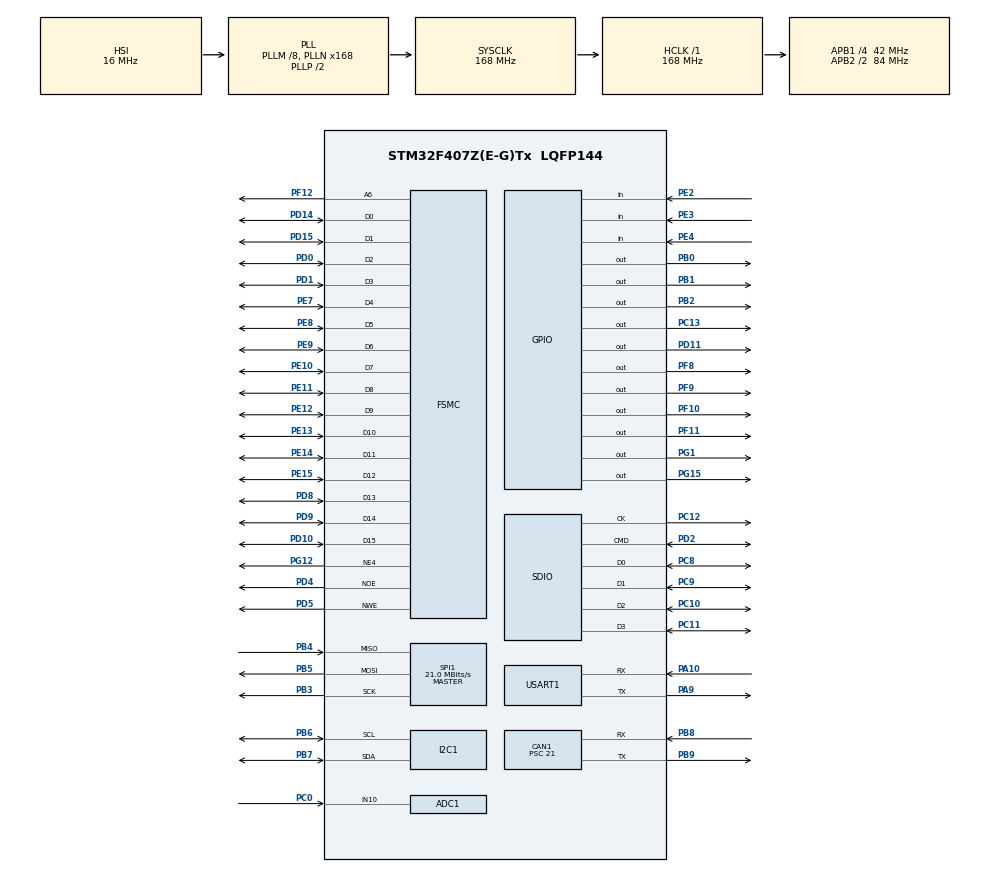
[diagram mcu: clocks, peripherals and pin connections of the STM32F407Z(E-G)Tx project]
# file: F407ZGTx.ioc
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ADC1.Channel-0\#ChannelRegularConversion=ADC_CHANNEL_10
ADC1.ClockPrescaler=ADC_CLOCK_SYNC_PCLK_DIV6
ADC1.ExternalTrigConv=ADC_EXTERNALTRIGCONV_T2_TRGO
ADC1.NbrOfConversion=1
ADC1.NbrOfConversionFlag=1
ADC1.Rank-0\#ChannelRegularConversion=1
ADC1.SamplingTime-0\#ChannelRegularConversion=ADC_SAMPLETIME_480CYCLES
ADC1.master=1
CAN1.ABOM=ENABLE
CAN1.BS1=CAN_BS1_13TQ
CAN1.BS2=CAN_BS2_2TQ
CAN1.CalculateBaudRate=125000
CAN1.CalculateTimeBit=8000
CAN1.CalculateTimeQuantum=500.0
CAN1.Mode=CAN_MODE_LOOPBACK
CAN1.NART=ENABLE
CAN1.Prescaler=21
Dma.ADC1.1.Direction=DMA_PERIPH_TO_MEMORY
Dma.ADC1.1.FIFOMode=DMA_FIFOMODE_DISABLE
Dma.ADC1.1.Instance=DMA2_Stream0
Dma.ADC1.1.MemDataAlignment=DMA_MDATAALIGN_HALFWORD
Dma.ADC1.1.MemInc=DMA_MINC_ENABLE
Dma.ADC1.1.Mode=DMA_CIRCULAR
Dma.ADC1.1.PeriphDataAlignment=DMA_PDATAALIGN_HALFWORD
Dma.ADC1.1.PeriphInc=DMA_PINC_DISABLE
Dma.ADC1.1.Priority=DMA_PRIORITY_LOW
Dma.Request0=USART1_RX
Dma.Request1=ADC1
Dma.USART1_RX.0.Direction=DMA_PERIPH_TO_MEMORY
Dma.USART1_RX.0.FIFOMode=DMA_FIFOMODE_DISABLE
Dma.USART1_RX.0.Instance=DMA2_Stream2
Dma.USART1_RX.0.MemDataAlignment=DMA_MDATAALIGN_BYTE
Dma.USART1_RX.0.MemInc=DMA_MINC_ENABLE
Dma.USART1_RX.0.Mode=DMA_NORMAL
Dma.USART1_RX.0.PeriphDataAlignment=DMA_PDATAALIGN_BYTE
Dma.USART1_RX.0.PeriphInc=DMA_PINC_DISABLE
Dma.USART1_RX.0.Priority=DMA_PRIORITY_LOW
FREERTOS.Queues01=q_LedReq,4,LedReq_t,0,Dynamic,NULL,NULL;q_KeyMsg,16,KeyMsg_t,0,Dynamic,NULL,NULL;q_TouchMsg,16,TouchMsg_t,0,Dynamic,NULL,NULL;q_UiMsg,8,UiMsg_t,0,Dynamic,NULL,NULL;q_Usart1RxMsg,8,UartMsg_t,0,Dynamic,NULL,NULL;q_Usart1TxMsg,8,UartMsg_t,0,Dynamic,NULL,NULL
FREERTOS.Tasks01=defaultTask,8,128,StartDefaultTask,Default,NULL,Dynamic,NULL,NULL;t_Lcd_Disp,16,1536,Lcd_Disp,As weak,NULL,Dynamic,NULL,NULL;t_Led_Disp,16,128,Led_Disp,As weak,NULL,Dynamic,NULL,NULL;t_Key_Proc,32,256,Key_Proc,As weak,NULL,Dynamic,NULL,NULL;t_Touch_Proc,32,256,Touch_Proc,As weak,NULL,Dynamic,NULL,NULL;t_Uart_Send,16,256,Uart_Send,As weak,NULL,Dynamic,NULL,NULL;t_Uart_Recv,16,256,Uart_Recv,As weak,NULL,Dynamic,NULL,NULL
FREERTOS.configTOTAL_HEAP_SIZE=32768
FSMC.AddressSetupTime4=3
FSMC.BusTurnAroundDuration4=0
FSMC.DataSetupTime4=20
FSMC.ExtendedAddressSetupTime4=9
FSMC.ExtendedBusTurnAroundDuration4=0
FSMC.ExtendedDataSetupTime4=8
FSMC.ExtendedMode4=FSMC_EXTENDED_MODE_ENABLE
Mcu.Family=STM32F4
Mcu.Name=STM32F407Z(E-G)Tx
Mcu.Package=LQFP144
NVIC.CAN1_RX0_IRQn=true\:5\:0\:false\:false\:true\:true\:true\:true\:true
NVIC.CAN1_SCE_IRQn=true\:5\:0\:false\:false\:true\:true\:true\:true\:true
NVIC.DMA2_Stream0_IRQn=true\:5\:0\:false\:false\:true\:true\:false\:true\:true
NVIC.DMA2_Stream2_IRQn=true\:5\:0\:false\:false\:true\:true\:false\:true\:true
NVIC.PriorityGroup=NVIC_PRIORITYGROUP_4
NVIC.TIM6_DAC_IRQn=true\:15\:0\:false\:false\:true\:false\:false\:true\:true
NVIC.TimeBase=TIM6_DAC_IRQn
NVIC.TimeBaseIP=TIM6
NVIC.USART1_IRQn=true\:5\:0\:false\:false\:true\:true\:true\:true\:true
PA10.Mode=Asynchronous
PA10.Signal=USART1_RX
PA13.Mode=Serial_Wire
PA13.Signal=SYS_JTMS-SWDIO
PA14.Mode=Serial_Wire
PA14.Signal=SYS_JTCK-SWCLK
PA9.Mode=Asynchronous
PA9.Signal=USART1_TX
PB0.Signal=GPIO_Output
PB1.Signal=GPIO_Output
PB2.Signal=GPIO_Output
PB3.Mode=Full_Duplex_Master
PB3.Signal=SPI1_SCK
PB4.Mode=Full_Duplex_Master
PB4.Signal=SPI1_MISO
PB5.Mode=Full_Duplex_Master
PB5.Signal=SPI1_MOSI
PB6.Mode=I2C
PB6.Signal=I2C1_SCL
PB7.Mode=I2C
PB7.Signal=I2C1_SDA
PB8.Mode=CAN_Activate
PB8.Signal=CAN1_RX
PB9.Mode=CAN_Activate
PB9.Signal=CAN1_TX
PC0.Signal=ADCx_IN10
PC10.Mode=SD_4_bits_Wide_bus
PC10.Signal=SDIO_D2
PC11.Mode=SD_4_bits_Wide_bus
PC11.Signal=SDIO_D3
PC12.Mode=SD_4_bits_Wide_bus
PC12.Signal=SDIO_CK
PC13-ANTI_TAMP.Signal=GPIO_Output
PC14-OSC32_IN.Mode=LSE-External-Oscillator
PC14-OSC32_IN.Signal=RCC_OSC32_IN
PC15-OSC32_OUT.Mode=LSE-External-Oscillator
PC15-OSC32_OUT.Signal=RCC_OSC32_OUT
PC8.Mode=SD_4_bits_Wide_bus
PC8.Signal=SDIO_D0
PC9.Mode=SD_4_bits_Wide_bus
PC9.Signal=SDIO_D1
PD0.Signal=FSMC_D2_DA2
PD1.Signal=FSMC_D3_DA3
PD10.Signal=FSMC_D15_DA15
PD11.Signal=GPIO_Output
PD14.Signal=FSMC_D0_DA0
PD15.Signal=FSMC_D1_DA1
PD2.Mode=SD_4_bits_Wide_bus
PD2.Signal=SDIO_CMD
PD4.Signal=FSMC_NOE
PD5.Signal=FSMC_NWE
PD8.Signal=FSMC_D13_DA13
PD9.Signal=FSMC_D14_DA14
PE10.Signal=FSMC_D7_DA7
PE11.Signal=FSMC_D8_DA8
PE12.Signal=FSMC_D9_DA9
PE13.Signal=FSMC_D10_DA10
PE14.Signal=FSMC_D11_DA11
PE15.Signal=FSMC_D12_DA12
PE2.GPIO_PuPd=GPIO_PULLUP
PE2.Signal=GPIO_Input
PE3.GPIO_PuPd=GPIO_PULLUP
PE3.Signal=GPIO_Input
PE4.GPIO_PuPd=GPIO_PULLUP
PE4.Signal=GPIO_Input
PE7.Signal=FSMC_D4_DA4
PE8.Signal=FSMC_D5_DA5
PE9.Signal=FSMC_D6_DA6
PF10.PinState=GPIO_PIN_SET
PF10.Signal=GPIO_Output
PF11.Signal=GPIO_Output
PF12.Signal=FSMC_A6
PF8.PinState=GPIO_PIN_SET
PF8.Signal=GPIO_Output
PF9.PinState=GPIO_PIN_SET
PF9.Signal=GPIO_Output
PG1.Signal=GPIO_Output
PG12.Mode=NorPsramChipSelect4_4
PG12.Signal=FSMC_NE4
PG15.Signal=GPIO_Output
PH0-OSC_IN.Mode=HSE-External-Oscillator
PH0-OSC_IN.Signal=RCC_OSC_IN
PH1-OSC_OUT.Mode=HSE-External-Oscillator
PH1-OSC_OUT.Signal=RCC_OSC_OUT
ProjectManager.HeapSize=0x200
ProjectManager.StackSize=0x400
ProjectManager.TargetToolchain=Makefile
RCC.48MHZClocksFreq_Value=48000000
RCC.AHBFreq_Value=168000000
RCC.APB1CLKDivider=RCC_HCLK_DIV4
RCC.APB1Freq_Value=42000000
RCC.APB1TimFreq_Value=84000000
RCC.APB2CLKDivider=RCC_HCLK_DIV2
RCC.APB2Freq_Value=84000000
RCC.APB2TimFreq_Value=168000000
RCC.CortexFreq_Value=168000000
RCC.HCLKFreq_Value=168000000
RCC.HSE_VALUE=25000000
RCC.HSI_VALUE=16000000
RCC.PLLM=8
RCC.PLLN=168
RCC.PLLQ=7
RCC.RCC_RTC_Clock_Source=RCC_RTCCLKSOURCE_LSE
RCC.RCC_RTC_Clock_SourceVirtual=RCC_RTCCLKSOURCE_LSE
RCC.SYSCLKFreq_VALUE=168000000
RCC.SYSCLKSource=RCC_SYSCLKSOURCE_PLLCLK
RCC.VCOOutputFreq_Value=336000000
RTC.Date=5
RTC.Hours=12
RTC.Minutes=59
RTC.Month=RTC_MONTH_OCTOBER
RTC.Seconds=50
RTC.Year=26
SH.ADCx_IN10.0=ADC1_IN10,IN10
SH.FSMC_A6.0=FSMC_A6,A6_4
SH.FSMC_D0_DA0.0=FSMC_D0,16b-d4
SH.FSMC_D10_DA10.0=FSMC_D10,16b-d4
SH.FSMC_D11_DA11.0=FSMC_D11,16b-d4
SH.FSMC_D12_DA12.0=FSMC_D12,16b-d4
SH.FSMC_D13_DA13.0=FSMC_D13,16b-d4
SH.FSMC_D14_DA14.0=FSMC_D14,16b-d4
SH.FSMC_D15_DA15.0=FSMC_D15,16b-d4
SH.FSMC_D1_DA1.0=FSMC_D1,16b-d4
SH.FSMC_D2_DA2.0=FSMC_D2,16b-d4
SH.FSMC_D3_DA3.0=FSMC_D3,16b-d4
SH.FSMC_D4_DA4.0=FSMC_D4,16b-d4
SH.FSMC_D5_DA5.0=FSMC_D5,16b-d4
SH.FSMC_D6_DA6.0=FSMC_D6,16b-d4
SH.FSMC_D7_DA7.0=FSMC_D7,16b-d4
SH.FSMC_D8_DA8.0=FSMC_D8,16b-d4
SH.FSMC_D9_DA9.0=FSMC_D9,16b-d4
SH.FSMC_NOE.0=FSMC_NOE,Lcd4
SH.FSMC_NWE.0=FSMC_NWE,Lcd4
SPI1.BaudRatePrescaler=SPI_BAUDRATEPRESCALER_4
SPI1.CLKPhase=SPI_PHASE_2EDGE
SPI1.CLKPolarity=SPI_POLARITY_HIGH
SPI1.CalculateBaudRate=21.0 MBits/s
SPI1.Direction=SPI_DIRECTION_2LINES
SPI1.Mode=SPI_MODE_MASTER
SPI1.VirtualType=VM_MASTER
TIM2.Period=399
TIM2.Prescaler=8399
TIM2.TIM_MasterOutputTrigger=TIM_TRGO_UPDATE
USART1.VirtualMode=VM_ASYNC
VP_CRC_VS_CRC.Mode=CRC_Activate
VP_FATFS_VS_SDIO.Mode=SDIO
VP_FREERTOS_VS_CMSIS_V2.Mode=CMSIS_V2
VP_RTC_VS_RTC_Activate.Mode=RTC_Enabled
VP_RTC_VS_RTC_Calendar.Mode=RTC_Calendar
VP_SYS_VS_tim6.Mode=TIM6
VP_TIM2_VS_ClockSourceINT.Mode=Internal
board=custom

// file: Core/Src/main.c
/* USER CODE BEGIN Header */
/**
  ******************************************************************************
  * @file           : main.c
  * @brief          : Main program body
  ******************************************************************************
  * @attention
  *
  * Copyright (c) 2026 STMicroelectronics.
  * All rights reserved.
  *
  * This software is licensed under terms that can be found in the LICENSE file
  * in the root directory of this software component.
  * If no LICENSE file comes with this software, it is provided AS-IS.
  *
  ******************************************************************************
  */
/* USER CODE END Header */
#include "main.h"
#include "cmsis_os.h"
#include "adc.h"
#include "can.h"
#include "crc.h"
#include "dma.h"
#include "fatfs.h"
#include "i2c.h"
#include "rtc.h"
#include "sdio.h"
#include "spi.h"
#include "tim.h"
#include "usart.h"
#include "gpio.h"
#include "fsmc.h"

void SystemClock_Config(void);
void MX_FREERTOS_Init(void);

int main(void)
{

  /* MCU Configuration--------------------------------------------------------*/

  /* Reset of all peripherals, Initializes the Flash interface and the Systick. */
  HAL_Init();

  /* Configure the system clock */
  SystemClock_Config();

  /* Initialize all configured peripherals */
  MX_GPIO_Init();
  MX_DMA_Init();
  MX_FSMC_Init();
  MX_I2C1_Init();
  MX_SPI1_Init();
  MX_USART1_UART_Init();
  MX_SDIO_SD_Init();
  MX_FATFS_Init();
  MX_CAN1_Init();
  MX_CRC_Init();
  MX_RTC_Init();
  MX_ADC1_Init();
  MX_TIM2_Init();

  /* Init scheduler */
  osKernelInitialize();  /* Call init function for freertos objects (in cmsis_os2.c) */
  MX_FREERTOS_Init();

  /* Start scheduler */
  osKernelStart();

  /* We should never get here as control is now taken by the scheduler */

  /* Infinite loop */
  while (1)
  {

  }
}

void SystemClock_Config(void)
{
  RCC_OscInitTypeDef RCC_OscInitStruct = {0};
  RCC_ClkInitTypeDef RCC_ClkInitStruct = {0};

  /** Configure the main internal regulator output voltage
  */
  __HAL_RCC_PWR_CLK_ENABLE();
  __HAL_PWR_VOLTAGESCALING_CONFIG(PWR_REGULATOR_VOLTAGE_SCALE1);

  /** Initializes the RCC Oscillators according to the specified parameters
  * in the RCC_OscInitTypeDef structure.
  */
  RCC_OscInitStruct.OscillatorType = RCC_OSCILLATORTYPE_HSI|RCC_OSCILLATORTYPE_LSE;
  RCC_OscInitStruct.LSEState = RCC_LSE_ON;
  RCC_OscInitStruct.HSIState = RCC_HSI_ON;
  RCC_OscInitStruct.HSICalibrationValue = RCC_HSICALIBRATION_DEFAULT;
  RCC_OscInitStruct.PLL.PLLState = RCC_PLL_ON;
  RCC_OscInitStruct.PLL.PLLSource = RCC_PLLSOURCE_HSI;
  RCC_OscInitStruct.PLL.PLLM = 8;
  RCC_OscInitStruct.PLL.PLLN = 168;
  RCC_OscInitStruct.PLL.PLLP = RCC_PLLP_DIV2;
  RCC_OscInitStruct.PLL.PLLQ = 7;
  if (HAL_RCC_OscConfig(&RCC_OscInitStruct) != HAL_OK)
  {
    Error_Handler();
  }

  /** Initializes the CPU, AHB and APB buses clocks
  */
  RCC_ClkInitStruct.ClockType = RCC_CLOCKTYPE_HCLK|RCC_CLOCKTYPE_SYSCLK
                              |RCC_CLOCKTYPE_PCLK1|RCC_CLOCKTYPE_PCLK2;
  RCC_ClkInitStruct.SYSCLKSource = RCC_SYSCLKSOURCE_PLLCLK;
  RCC_ClkInitStruct.AHBCLKDivider = RCC_SYSCLK_DIV1;
  RCC_ClkInitStruct.APB1CLKDivider = RCC_HCLK_DIV4;
  RCC_ClkInitStruct.APB2CLKDivider = RCC_HCLK_DIV2;

  if (HAL_RCC_ClockConfig(&RCC_ClkInitStruct, FLASH_LATENCY_5) != HAL_OK)
  {
    Error_Handler();
  }
}

void HAL_TIM_PeriodElapsedCallback(TIM_HandleTypeDef *htim)
{
  if (htim->Instance == TIM6)
  {
    HAL_IncTick();
  }
}

void Error_Handler(void)
{
  __disable_irq();
  while (1)
  {
  }
}

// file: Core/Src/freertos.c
/* USER CODE BEGIN Header */
/**
  ******************************************************************************
  * File Name          : freertos.c
  * Description        : Code for freertos applications
  ******************************************************************************
  * @attention
  *
  * Copyright (c) 2026 STMicroelectronics.
  * All rights reserved.
  *
  * This software is licensed under terms that can be found in the LICENSE file
  * in the root directory of this software component.
  * If no LICENSE file comes with this software, it is provided AS-IS.
  *
  ******************************************************************************
  */
/* USER CODE END Header */

#include "FreeRTOS.h"
#include "task.h"
#include "main.h"
#include "cmsis_os.h"

/* USER CODE BEGIN Includes */
#include "led.h"
#include "key.h"
#include "touch.h"
#include "ui_msg.h"
#include "uart_task.h"
/* USER CODE END Includes */

/* Definitions for defaultTask */
osThreadId_t defaultTaskHandle;
const osThreadAttr_t defaultTask_attributes = {
  .name = "defaultTask",
  .stack_size = 128 * 4,
  .priority = (osPriority_t) osPriorityLow,
};
/* Definitions for t_Lcd_Disp */
osThreadId_t t_Lcd_DispHandle;
const osThreadAttr_t t_Lcd_Disp_attributes = {
  .name = "t_Lcd_Disp",
  .stack_size = 1536 * 4,
  .priority = (osPriority_t) osPriorityBelowNormal,
};
/* Definitions for t_Led_Disp */
osThreadId_t t_Led_DispHandle;
const osThreadAttr_t t_Led_Disp_attributes = {
  .name = "t_Led_Disp",
  .stack_size = 128 * 4,
  .priority = (osPriority_t) osPriorityBelowNormal,
};
/* Definitions for t_Key_Proc */
osThreadId_t t_Key_ProcHandle;
const osThreadAttr_t t_Key_Proc_attributes = {
  .name = "t_Key_Proc",
  .stack_size = 256 * 4,
  .priority = (osPriority_t) osPriorityAboveNormal,
};
/* Definitions for t_Touch_Proc */
osThreadId_t t_Touch_ProcHandle;
const osThreadAttr_t t_Touch_Proc_attributes = {
  .name = "t_Touch_Proc",
  .stack_size = 256 * 4,
  .priority = (osPriority_t) osPriorityAboveNormal,
};
/* Definitions for t_Uart_Send */
osThreadId_t t_Uart_SendHandle;
const osThreadAttr_t t_Uart_Send_attributes = {
  .name = "t_Uart_Send",
  .stack_size = 256 * 4,
  .priority = (osPriority_t) osPriorityBelowNormal,
};
/* Definitions for t_Uart_Recv */
osThreadId_t t_Uart_RecvHandle;
const osThreadAttr_t t_Uart_Recv_attributes = {
  .name = "t_Uart_Recv",
  .stack_size = 256 * 4,
  .priority = (osPriority_t) osPriorityBelowNormal,
};
/* Definitions for q_LedReq */
osMessageQueueId_t q_LedReqHandle;
const osMessageQueueAttr_t q_LedReq_attributes = {
  .name = "q_LedReq"
};
/* Definitions for q_KeyMsg */
osMessageQueueId_t q_KeyMsgHandle;
const osMessageQueueAttr_t q_KeyMsg_attributes = {
  .name = "q_KeyMsg"
};
/* Definitions for q_TouchMsg */
osMessageQueueId_t q_TouchMsgHandle;
const osMessageQueueAttr_t q_TouchMsg_attributes = {
  .name = "q_TouchMsg"
};
/* Definitions for q_UiMsg */
osMessageQueueId_t q_UiMsgHandle;
const osMessageQueueAttr_t q_UiMsg_attributes = {
  .name = "q_UiMsg"
};
/* Definitions for q_Usart1RxMsg */
osMessageQueueId_t q_Usart1RxMsgHandle;
const osMessageQueueAttr_t q_Usart1RxMsg_attributes = {
  .name = "q_Usart1RxMsg"
};
/* Definitions for q_Usart1TxMsg */
osMessageQueueId_t q_Usart1TxMsgHandle;
const osMessageQueueAttr_t q_Usart1TxMsg_attributes = {
  .name = "q_Usart1TxMsg"
};

void StartDefaultTask(void *argument);
void Lcd_Disp(void *argument);
void Led_Disp(void *argument);
void Key_Proc(void *argument);
void Touch_Proc(void *argument);
void Uart_Send(void *argument);
void Uart_Recv(void *argument);

void MX_FREERTOS_Init(void); /* (MISRA C 2004 rule 8.1) */

void MX_FREERTOS_Init(void) {

  /* Create the queue(s) */
  /* creation of q_LedReq */
  q_LedReqHandle = osMessageQueueNew (4, sizeof(LedReq_t), &q_LedReq_attributes);

  /* creation of q_KeyMsg */
  q_KeyMsgHandle = osMessageQueueNew (16, sizeof(KeyMsg_t), &q_KeyMsg_attributes);

  /* creation of q_TouchMsg */
  q_TouchMsgHandle = osMessageQueueNew (16, sizeof(TouchMsg_t), &q_TouchMsg_attributes);

  /* creation of q_UiMsg */
  q_UiMsgHandle = osMessageQueueNew (8, sizeof(UiMsg_t), &q_UiMsg_attributes);

  /* creation of q_Usart1RxMsg */
  q_Usart1RxMsgHandle = osMessageQueueNew (8, sizeof(UartMsg_t), &q_Usart1RxMsg_attributes);

  /* creation of q_Usart1TxMsg */
  q_Usart1TxMsgHandle = osMessageQueueNew (8, sizeof(UartMsg_t), &q_Usart1TxMsg_attributes);

  /* Create the thread(s) */
  /* creation of defaultTask */
  defaultTaskHandle = osThreadNew(StartDefaultTask, NULL, &defaultTask_attributes);

  /* creation of t_Lcd_Disp */
  t_Lcd_DispHandle = osThreadNew(Lcd_Disp, NULL, &t_Lcd_Disp_attributes);

  /* creation of t_Led_Disp */
  t_Led_DispHandle = osThreadNew(Led_Disp, NULL, &t_Led_Disp_attributes);

  /* creation of t_Key_Proc */
  t_Key_ProcHandle = osThreadNew(Key_Proc, NULL, &t_Key_Proc_attributes);

  /* creation of t_Touch_Proc */
  t_Touch_ProcHandle = osThreadNew(Touch_Proc, NULL, &t_Touch_Proc_attributes);

  /* creation of t_Uart_Send */
  t_Uart_SendHandle = osThreadNew(Uart_Send, NULL, &t_Uart_Send_attributes);

  /* creation of t_Uart_Recv */
  t_Uart_RecvHandle = osThreadNew(Uart_Recv, NULL, &t_Uart_Recv_attributes);

}

void StartDefaultTask(void *argument)
{
  /* USER CODE BEGIN StartDefaultTask */
  /* Infinite loop */
  for(;;)
  {
    osDelay(1000);
  }
  /* USER CODE END StartDefaultTask */
}

__weak void Lcd_Disp(void *argument)
{
  for(;;)
  {
    osDelay(1);
  }
}

__weak void Led_Disp(void *argument)
{
  for(;;)
  {
    osDelay(1);
  }
}

__weak void Key_Proc(void *argument)
{
  for(;;)
  {
    osDelay(1);
  }
}

__weak void Touch_Proc(void *argument)
{
  for(;;)
  {
    osDelay(1);
  }
}

__weak void Uart_Send(void *argument)
{
  for(;;)
  {
    osDelay(1);
  }
}

__weak void Uart_Recv(void *argument)
{
  for(;;)
  {
    osDelay(1);
  }
}
